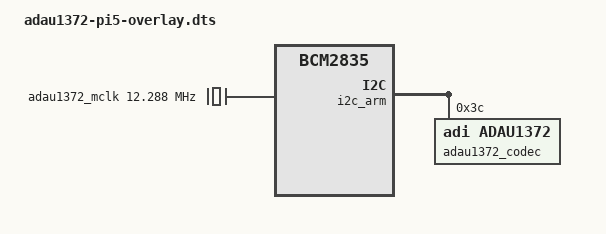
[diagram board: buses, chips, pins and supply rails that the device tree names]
// SPDX-License-Identifier: GPL-2.0
//
// ADAU1372 EVB (EVAL-ADAU1372Z) <-> Raspberry Pi 5 / CM5 (RP1), CODEC IS CLOCK PROVIDER.
// Capture-oriented: 4 single-ended analog inputs -> TDM4 -> Pi.
//
// *** Framing changed to PLAIN STEREO I2S on 2026-09-17. ***
// History, all measured on this rig:
//   - TDM4 (128 BCLK/frame) streamed with no XRUN but was never slot-aligned:
//     a per-slot tone test gave a DIFFERENT map on each run, tones mixed across
//     slot boundaries, samples clipping to +-2^31, and only 2 of 4 channels ever
//     carrying data.
//   - simple-audio-card,frame-inversion (LR_POL = 1, verified SAI_1 = 0x11) did
//     not fix it.  Neither did 2-channel capture, nor dropping BCLK from
//     6.144 MHz to 1.024 MHz (which rules out signal integrity).  A search over
//     all 128 bit positions found no constant offset.
//   - The RP1 I2S block wants a 64-BCLK frame (64 fs), so the codec is now left
//     in plain I2S: 2 slots x 32 bits.  With no dai-tdm-slot-* properties the
//     driver never calls set_tdm_slot, so SAI stays I2S and SOUT_CONTROL0 stays
//     0x00 (all slots enabled) - note that this also sidesteps the trap where a
//     missing tx-mask makes adau1372_set_tdm_slot() write 0xFF and disable every
//     output slot silently.
//
// Clock direction is chosen by picking the RP1 block, not by configuring one
// (dwc-i2s.c takes DW_I2S_MASTER/SLAVE from a synthesis parameter):
//     i2s_clk_producer -> rp1_i2s0   Pi drives BCLK/LRCLK
//     i2s_clk_consumer -> rp1_i2s1   codec drives BCLK/LRCLK   <-- used here
//
// Build:   dtc -@ -I dts -O dtb -o adau1372-pi5.dtbo adau1372-pi5-overlay.dts
// Install: sudo cp adau1372-pi5.dtbo /boot/firmware/overlays/
// config.txt:
//     dtparam=i2c_arm=on
//     dtoverlay=adau1372-pi5
//     dtoverlay=adau1372-pi5,addr=0x3d,mclk=24576000     # if strapped/clocked differently

/dts-v1/;
/plugin/;

/ {
	compatible = "brcm,bcm2835";

	fragment@0 {
		target = <&i2s_clk_consumer>;
		__overlay__ {
			status = "okay";
		};
	};

	// The EVB clocks itself; the codec driver only needs to be told the rate.
	// 12.288 MHz is PROVISIONAL - confirm against the EVB oscillator (UG-807).
	// 12.288 and 24.576 MHz are used directly; anything else engages the PLL.
	fragment@1 {
		target-path = "/";
		__overlay__ {
			adau1372_mclk: adau1372-mclk {
				compatible = "fixed-clock";
				#clock-cells = <0>;
				clock-frequency = <12288000>;
			};
		};
	};

	fragment@2 {
		target = <&i2c_arm>;
		__overlay__ {
			#address-cells = <1>;
			#size-cells = <0>;
			status = "okay";

			adau1372_codec: audio-codec@3c {
				compatible = "adi,adau1372";
				reg = <0x3c>;			// 0x3C..0x3F per ADDR1/ADDR0 strapping
				#sound-dai-cells = <0>;
				clocks = <&adau1372_mclk>;
				clock-names = "mclk";
				status = "okay";
			};
		};
	};

	fragment@3 {
		target = <&sound>;
		__overlay__ {
			compatible = "simple-audio-card";
			i2s-controller = <&i2s_clk_consumer>;
			status = "okay";

			simple-audio-card,name = "adau1372";
			// PLAIN STEREO I2S: 2 slots x 32 bits = 64 BCLK per frame (64 fs).
			// The RP1 I2S block wants a 64-BCLK frame; the codec was previously
			// framing TDM4 = 128 BCLK, and that mismatch produced a garbage,
			// non-deterministic slot map with only 2 of 4 channels carrying data
			// (measured 2026-09-17).  With no dai-tdm-slot-* properties the driver
			// leaves SAI in I2S mode and SOUT_CONTROL0 at 0x00 (all slots enabled).
			// i2s.  left_j was tried on 2026-09-17 and REVERTED: with left_j the DAC
			// output was audibly huge noise (Peter, by ear) while the identical
			// file on a USB dongle was clean tones.  A digital loopback cannot
			// catch this - it passes bits through unchanged whether the
			// justification is right or wrong - so it took ears to find.
			// Original left_j rationale, now known to be wrong:
			// With "i2s" the slot map was right but the bits within each slot
			// wrapped (purity 13-18%, peaks pinned to +-2^31 from a -12 dBFS
			// source), which is what a one-bit data offset does.
			// Driver effect: SAI_0 delay field -> 0x40, and LR_POL inverts.
			simple-audio-card,format = "i2s";


			simple-audio-card,bitclock-master = <&snd_codec>;
			simple-audio-card,frame-master = <&snd_codec>;

			simple-audio-card,widgets =
				"Microphone", "Mic Jack",
				"Line", "Accel X",
				"Line", "Accel Y",
				"Line", "Accel Z";

			// Pairs are sink, source. The MICBIAS0 line is what turns the
			// bias supply on - it is a DAPM supply with no amixer control.
			simple-audio-card,routing =
				"AIN0", "Mic Jack",
				"Mic Jack", "MICBIAS0",
				"AIN1", "Accel X",
				"AIN2", "Accel Y",
				"AIN3", "Accel Z";

			sai_cpu: simple-audio-card,cpu {
				sound-dai = <&i2s_clk_consumer>;
			};

			snd_codec: simple-audio-card,codec {
				sound-dai = <&adau1372_codec>;
			};
		};
	};

	__overrides__ {
		addr  = <&adau1372_codec>,"reg:0";
		mclk  = <&adau1372_mclk>,"clock-frequency:0";
	};
};
